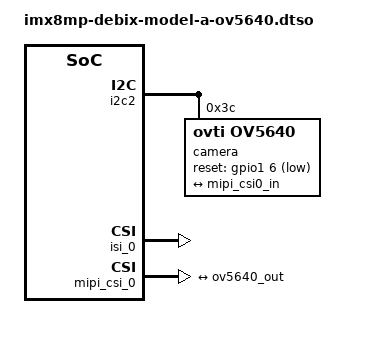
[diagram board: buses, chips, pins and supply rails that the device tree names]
// SPDX-License-Identifier: (GPL-2.0+ OR MIT)
/*
 * OV5640 camera (2 lanes) on the DEBIX Model A MIPI-CSI connector,
 * captured through ISI.
 *
 * The vendor DTS drives camera power-down on GPIO2_IO11. Mainline uses
 * that pad as the HYM8563 RTC interrupt, so power-down is not described.
 */

/dts-v1/;
/plugin/;

#include <dt-bindings/clock/imx8mp-clock.h>
#include <dt-bindings/gpio/gpio.h>
#include "../imx8mp-pinfunc.h"

&i2c2 {
	#address-cells = <1>;
	#size-cells = <0>;
	status = "okay";

	camera@3c {
		compatible = "ovti,ov5640";
		reg = <0x3c>;
		pinctrl-names = "default";
		pinctrl-0 = <&pinctrl_csi0>;
		clocks = <&clk IMX8MP_CLK_IPP_DO_CLKO2>;
		clock-names = "xclk";
		assigned-clocks = <&clk IMX8MP_CLK_IPP_DO_CLKO2>;
		assigned-clock-parents = <&clk IMX8MP_CLK_24M>;
		assigned-clock-rates = <24000000>;
		reset-gpios = <&gpio1 6 GPIO_ACTIVE_LOW>;

		port {
			ov5640_out: endpoint {
				remote-endpoint = <&mipi_csi0_in>;
				clock-lanes = <0>;
				data-lanes = <1 2>;
			};
		};
	};
};

&isi_0 {
	status = "okay";
};

&mipi_csi_0 {
	status = "okay";

	ports {
		port@0 {
			reg = <0>;

			mipi_csi0_in: endpoint {
				remote-endpoint = <&ov5640_out>;
				data-lanes = <1 2>;
			};
		};
	};
};

&iomuxc {
	pinctrl_csi0: csi0grp {
		fsl,pins = <
			MX8MP_IOMUXC_GPIO1_IO06__GPIO1_IO06		0x19
			MX8MP_IOMUXC_GPIO1_IO15__CCM_CLKO2		0x59
		>;
	};
};
